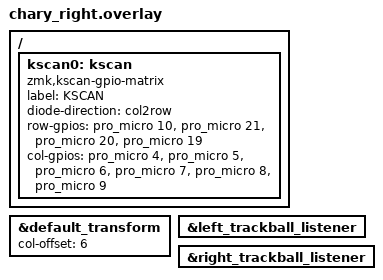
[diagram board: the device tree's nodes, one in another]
/*
 * Copyright (c) 2022 Duccio Breschi
 *
 * SPDX-License-Identifier: MIT
 */

#include "chary.dtsi"

&default_transform {
    col-offset = <6>;
};



/ {
    kscan0: kscan {
        compatible = "zmk,kscan-gpio-matrix";
        label = "KSCAN";
        diode-direction = "col2row";
       row-gpios
            = <&pro_micro 10 (GPIO_ACTIVE_HIGH | GPIO_PULL_DOWN)> // ROW0: D10
            , <&pro_micro 21 (GPIO_ACTIVE_HIGH | GPIO_PULL_DOWN)> // ROW1: D21
            , <&pro_micro 20 (GPIO_ACTIVE_HIGH | GPIO_PULL_DOWN)> // ROW2: D20
            , <&pro_micro 19 (GPIO_ACTIVE_HIGH | GPIO_PULL_DOWN)> // ROW3: D19
        ;
        col-gpios
            = <&pro_micro 4 GPIO_ACTIVE_HIGH> // COL0: D4
            , <&pro_micro 5 GPIO_ACTIVE_HIGH> // COL1: D5
            , <&pro_micro 6 GPIO_ACTIVE_HIGH> // COL2: D6
            , <&pro_micro 7 GPIO_ACTIVE_HIGH> // COL3: D7
            , <&pro_micro 8 GPIO_ACTIVE_HIGH> // COL4: D8
            , <&pro_micro 9 GPIO_ACTIVE_HIGH> // COL5: D9
        ;
    };

};

// Process both sensors on the central after input split forwarding.
&left_trackball_listener {
    status = "okay";
};

&right_trackball_listener {
    status = "okay";
};
